AUTOSAR XML (schema 00047)
package /AppSwComponent_Dcm/SwComponentType
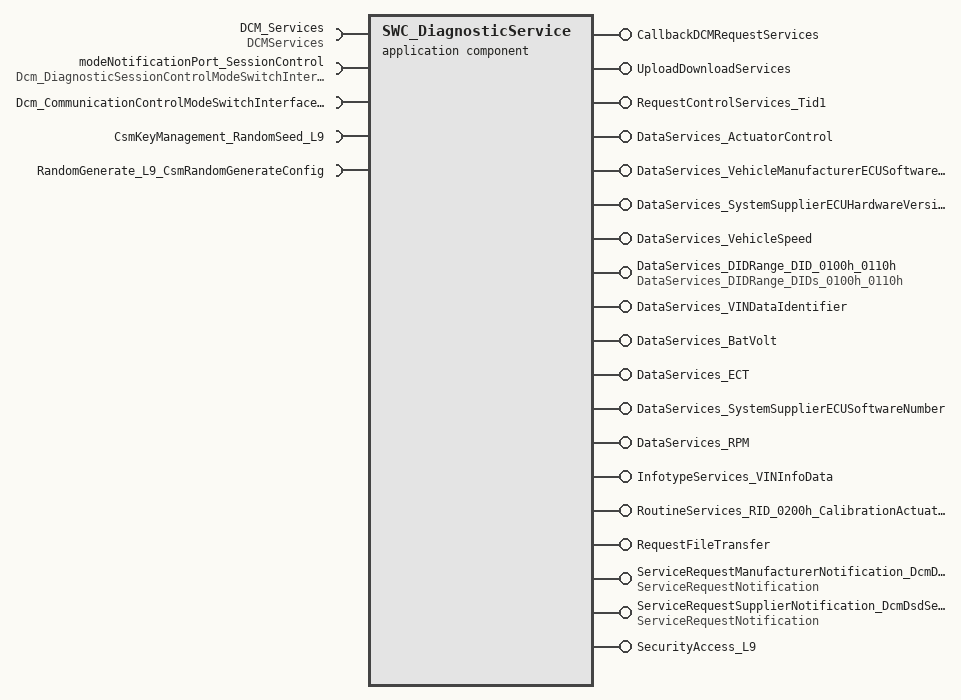
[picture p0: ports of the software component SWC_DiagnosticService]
  application sw component type SWC_DiagnosticService
    provide port CallbackDCMRequestServices: provided-com-specs=[{operation=StartProtocol, queue-length=1}, {operation=StopProtocol, queue-length=1}], provided-interface=CallbackDCMRequestServices
    require port DCM_Services: required-com-specs=[GetActiveProtocol, GetSesCtrlType, GetSecurityLevel, ResetToDefaultSession], required-interface=DCMServices
    require port modeNotificationPort_SessionControl: mode-switch-receiver-com-spec{enhanced-mode-api=true, mode-group=Dcm_DiagnosticSessionControlModeSwitchInterface, supports-asynchronous-mode-switch=true}, required-interface=Dcm_DiagnosticSessionControlModeSwitchInterface
    17 x provide port:
      UploadDownloadServices: provided-interface=UploadDownloadServices
        provided-com-specs:
          operation=ProcessRequestDownload, queue-length=1
          operation=ProcessRequestTransferExit, queue-length=1
          operation=ProcessRequestUpload, queue-length=1
          operation=ProcessTransferDataRead, queue-length=1
          operation=ProcessTransferDataWrite, queue-length=1
      RequestControlServices_Tid1: server-com-spec{operation=RequestControl, queue-length=1}, provided-interface=RequestControlServices_Tid1
      DataServices_ActuatorControl: provided-interface=DataServices_ActuatorControl
        provided-com-specs:
          operation=ConditionCheckRead, queue-length=1
          operation=ReadData, queue-length=1
          operation=WriteData, queue-length=1
          operation=FreezeCurrentState, queue-length=1
          operation=ReturnControlToECU, queue-length=1
          operation=ShortTermAdjustment, queue-length=1
          operation=ResetToDefault, queue-length=1
      DataServices_VehicleManufacturerECUSoftwareVersionNumber: provided-com-specs=[{operation=ReadData, queue-length=1}, {operation=ConditionCheckRead, queue-length=1}], provided-interface=DataServices_VehicleManufacturerECUSoftwareVersionNumber
      DataServices_SystemSupplierECUHardwareVersionNumber: provided-com-specs=[{operation=ReadData, queue-length=1}, {operation=ConditionCheckRead, queue-length=1}], provided-interface=DataServices_SystemSupplierECUHardwareVersionNumber
      DataServices_VehicleSpeed: provided-interface=DataServices_VehicleSpeed
        provided-com-specs:
          operation=ReadData, queue-length=1
          operation=ConditionCheckRead, queue-length=1
          operation=GetScalingInformation, queue-length=1
      DataServices_DIDRange_DID_0100h_0110h: provided-interface=DataServices_DIDRange_DIDs_0100h_0110h
        provided-com-specs:
          operation=IsDidAvailable, queue-length=1
          operation=ReadDidData, queue-length=1
          operation=ReadDidRangeDataLength, queue-length=1
          operation=WriteDidData, queue-length=1
      DataServices_VINDataIdentifier: provided-interface=DataServices_VINDataIdentifier
        provided-com-specs:
          operation=ConditionCheckRead, queue-length=1
          operation=GetScalingInformation, queue-length=1
          operation=ReadData, queue-length=1
          operation=WriteData, queue-length=1
      DataServices_BatVolt: provided-interface=DataServices_BatVolt
        provided-com-specs:
          operation=ReadData, queue-length=1
          operation=ConditionCheckRead, queue-length=1
          operation=WriteData, queue-length=1
      DataServices_ECT: provided-interface=DataServices_ECT
        provided-com-specs:
          operation=ReadData, queue-length=1
          operation=WriteData, queue-length=1
          operation=ConditionCheckRead, queue-length=1
      DataServices_SystemSupplierECUSoftwareNumber: provided-com-specs=[{operation=ReadData, queue-length=1}, {operation=ConditionCheckRead, queue-length=1}], provided-interface=DataServices_SystemSupplierECUSoftwareNumber
      DataServices_RPM: provided-interface=DataServices_RPM
        provided-com-specs:
          operation=ReadData, queue-length=1
          operation=ConditionCheckRead, queue-length=1
          operation=FreezeCurrentState, queue-length=1
          operation=ReturnControlToECU, queue-length=1
          operation=ShortTermAdjustment, queue-length=1
          operation=WriteData, queue-length=1
      InfotypeServices_VINInfoData: server-com-spec{operation=GetInfotypeValueData, queue-length=1}, provided-interface=InfotypeServices_VINInfoData
      RoutineServices_RID_0200h_CalibrationActuator: provided-interface=RoutineServices_RID_0200h_CalibrationActuator
        provided-com-specs:
          operation=Start, queue-length=1
          operation=Stop, queue-length=1
          operation=RequestResults, queue-length=1
      RequestFileTransfer: provided-interface=RequestFileTransfer
        provided-com-specs:
          operation=ProcessRequestAddFile, queue-length=1
          operation=ProcessRequestDeleteFile, queue-length=1
          operation=ProcessRequestReadDir, queue-length=1
          operation=ProcessRequestReadFile, queue-length=1
          operation=ProcessRequestReplaceFile, queue-length=1
          operation=ReadFileOrDir, queue-length=1
          operation=WriteFile, queue-length=1
      ServiceRequestManufacturerNotification_DcmDsdServiceRequestManufacturerNotification0: provided-com-specs=[{operation=Confirmation, queue-length=1}, {operation=Indication, queue-length=1}], provided-interface=ServiceRequestNotification
      ServiceRequestSupplierNotification_DcmDsdServiceRequestSupplierNotification0: provided-com-specs=[{operation=Confirmation, queue-length=1}, {operation=Indication, queue-length=1}], provided-interface=ServiceRequestNotification
    require port Dcm_CommunicationControlModeSwitchInterface_ComMChannel_FD_CAN1: mode-switch-receiver-com-spec{enhanced-mode-api=true, mode-group=Dcm_CommunicationControlModeSwitchInterface_ComMChannel_FD_CAN1, supports-asynchronous-mode-switch=true}, required-interface=Dcm_CommunicationControlModeSwitchInterface_ComMChannel_FD_CAN1
    provide port SecurityAccess_L9: provided-com-specs=[{operation=CompareKey, queue-length=1}, {operation=GetSeed, queue-length=1}], provided-interface=SecurityAccess_L9
    require port CsmKeyManagement_RandomSeed_L9: client-com-spec=RandomSeed, required-interface=CsmKeyManagement_RandomSeed_L9
    require port RandomGenerate_L9_CsmRandomGenerateConfig: client-com-spec=RandomGenerate, required-interface=RandomGenerate_L9_CsmRandomGenerateConfig
    behavior InternalBehaviors_DiagnosticService: data-type-mapping=DcmDiagnosticSessionControl, handle-termination-and-restart=NO-SUPPORT
      operation invoked event OIE_CallbackDCMRequestServices_StartProtocol: start-on-event=CallbackDCMRequestServices_StartProtocol, operation=CallbackDCMRequestServices.StartProtocol
      operation invoked event OIE_CallbackDCMRequestServices_StopProtocol: start-on-event=CallbackDCMRequestServices_StopProtocol, operation=CallbackDCMRequestServices.StopProtocol
      swc mode switch event SMSE_Entry_DiagnosticSessionControlNotification_modeNotificationPort_SessionControl_DcmDiagnosticSessionControl_DCM_DEFAULT_SESSION: start-on-event=DiagnosticSessionControlNotification, activation=ON-ENTRY, mode=modeNotificationPort_SessionControl.Dcm_DiagnosticSessionControlModeSwitchInterface.DCM_DEFAULT_SESSION
      swc mode switch event SMSE_Entry_DiagnosticSessionControlNotification_modeNotificationPort_SessionControl_DcmDiagnosticSessionControl_DCM_EXTENDED_DIAGNOSTIC_SESSION: start-on-event=DiagnosticSessionControlNotification, activation=ON-ENTRY, mode=modeNotificationPort_SessionControl.Dcm_DiagnosticSessionControlModeSwitchInterface.DCM_EXTENDED_DIAGNOSTIC_SESSION
      59 x operation invoked event:
        OIE_UploadDownloadServices_ProcessTransferDataRead: start-on-event=UploadDownloadServices_ProcessTransferDataRead, operation=UploadDownloadServices.ProcessTransferDataRead
        OIE_UploadDownloadServices_ProcessRequestDownload: start-on-event=UploadDownloadServices_ProcessRequestDownload, operation=UploadDownloadServices.ProcessRequestDownload
        OIE_UploadDownloadServices_ProcessTransferDataWrite: start-on-event=UploadDownloadServices_ProcessTransferDataWrite, operation=UploadDownloadServices.ProcessTransferDataWrite
        OIE_UploadDownloadServices_ProcessRequestTransferExit: start-on-event=UploadDownloadServices_ProcessRequestTransferExit, operation=UploadDownloadServices.ProcessRequestTransferExit
        OIE_UploadDownloadServices_ProcessRequestUpload: start-on-event=UploadDownloadServices_ProcessRequestUpload, operation=UploadDownloadServices.ProcessRequestUpload
        OIE_RequestControlServices_Tid1_RequestControl: start-on-event=RequestControlServices_Tid1_RequestControl, operation=RequestControlServices_Tid1.RequestControl
        OIE_ActuatorControl_ReadData: start-on-event=ActuatorControl_ReadData, operation=DataServices_ActuatorControl.ReadData
        OIE_ActuatorControl_WriteData: start-on-event=ActuatorControl_WriteData, operation=DataServices_ActuatorControl.WriteData
        OIE_ActuatorControl_ConditionCheckRead: start-on-event=ActuatorControl_ConditionCheckRead, operation=DataServices_ActuatorControl.ConditionCheckRead
        OIE_ActuatorControl_ResetToDefault: start-on-event=ActuatorControl_ResetToDefault, operation=DataServices_ActuatorControl.ResetToDefault
        OIE_ActuatorControl_FreezeCurrentState: start-on-event=ActuatorContro_FreezeCurrentState, operation=DataServices_ActuatorControl.FreezeCurrentState
        OIE_ActuatorControl_ReturnControlToECU: start-on-event=ActuatorControl_ReturnControlToECU, operation=DataServices_ActuatorControl.ReturnControlToECU
        OIE_ActuatorControl_ShortTermAdjustment: start-on-event=ActuatorControl_ShortTermAdjustment, operation=DataServices_ActuatorControl.ShortTermAdjustment
        OIE_DID_0100h_0110h_ReadDidData: start-on-event=DID_0100h_0110h_ReadDidData, operation=DataServices_DIDRange_DID_0100h_0110h.ReadDidData
        OIE_DID_0100h_0110h_WriteDidData: start-on-event=DID_0100h_0110h_WriteDidData, operation=DataServices_DIDRange_DID_0100h_0110h.WriteDidData
        OIE_DID_0100h_0110h_IsDidAvailable: start-on-event=DID_0100h_0110h_IsDidAvailable, operation=DataServices_DIDRange_DID_0100h_0110h.IsDidAvailable
        OIE_DID_0100h_0110h_ReadDidRangeDataLength: start-on-event=DID_0100h_0110h_ReadDidRangeDataLength, operation=DataServices_DIDRange_DID_0100h_0110h.ReadDidRangeDataLength
        OIE_VehicleSpeed_GetScalingInformation: start-on-event=VehicleSpeed_GetScalingInformation, operation=DataServices_VehicleSpeed.GetScalingInformation
        OIE_VINDataIdentifier_ConditionCheckRead: start-on-event=VINDataIdentifier_ConditionCheckRead, operation=DataServices_VINDataIdentifier.ConditionCheckRead
        OIE_VehicleManufacturerECUSoftwareVersionNumber_ConditionCheckRead: start-on-event=VehicleManufacturerECUSoftwareVersionNumber_ConditionCheckRead, operation=DataServices_VehicleManufacturerECUSoftwareVersionNumber.ConditionCheckRead
        OIE_RPM_WriteData: start-on-event=RPM_WriteData, operation=DataServices_RPM.WriteData
        OIE_VINDataIdentifier_WriteData: start-on-event=VINDataIdentifier_WriteData, operation=DataServices_VINDataIdentifier.WriteData
        OIE_SystemSupplierECUHardwareVersionNumber_ReadData: start-on-event=SystemSupplierECUHardwareVersionNumber_ReadData, operation=DataServices_SystemSupplierECUHardwareVersionNumber.ReadData
        OIE_BatVolt_WriteData: start-on-event=BatVolt_WriteData, operation=DataServices_BatVolt.WriteData
        OIE_ECT_ReadData: start-on-event=ECT_ReadData, operation=DataServices_ECT.ReadData
        OIE_ECT_WriteData: start-on-event=ECT_WriteData, operation=DataServices_ECT.WriteData
        OIE_VehicleManufacturerECUSoftwareVersionNumber_ReadData: start-on-event=VehicleManufacturerECUSoftwareVersionNumber_ReadData, operation=DataServices_VehicleManufacturerECUSoftwareVersionNumber.ReadData
        OIE_SystemSupplierECUSoftwareNumber_ConditionCheckRead: start-on-event=SystemSupplierECUSoftwareNumber_ConditionCheckRead, operation=DataServices_SystemSupplierECUSoftwareNumber.ConditionCheckRead
        OIE_RPM_FreezeCurrentState: start-on-event=RPM_FreezeCurrentState, operation=DataServices_RPM.FreezeCurrentState
        OIE_BatVolt_ConditionCheckRead: start-on-event=BatVolt_ConditionCheckRead, operation=DataServices_BatVolt.ConditionCheckRead
        OIE_SystemSupplierECUHardwareVersionNumber_ConditionCheckRead: start-on-event=SystemSupplierECUHardwareVersionNumber_ConditionCheckRead, operation=DataServices_SystemSupplierECUHardwareVersionNumber.ConditionCheckRead
        OIE_BatVolt_ReadData: start-on-event=BatVolt_ReadData, operation=DataServices_BatVolt.ReadData
        OIE_RPM_ReadData: start-on-event=RPM_ReadData, operation=DataServices_RPM.ReadData
        OIE_VINDataIdentifier_ReadData: start-on-event=VINDataIdentifier_ReadData, operation=DataServices_VINDataIdentifier.ReadData
        OIE_RPM_ShortTermAdjustment: start-on-event=RPM_ShortTermAdjustment, operation=DataServices_RPM.ShortTermAdjustment
        OIE_RPM_ConditionCheckRead: start-on-event=RPM_ConditionCheckRead, operation=DataServices_RPM.ConditionCheckRead
        OIE_ECT_ConditionCheckRead: start-on-event=ECT_ConditionCheckRead, operation=DataServices_ECT.ConditionCheckRead
        OIE_VehicleSpeed_ConditionCheckRead: start-on-event=VehicleSpeed_ConditionCheckRead, operation=DataServices_VehicleSpeed.ConditionCheckRead
        OIE_RPM_ReturnControlToECU: start-on-event=RPM_ReturnControlToECU, operation=DataServices_RPM.ReturnControlToECU
        OIE_VehicleSpeed_ReadData: start-on-event=VehicleSpeed_ReadData, operation=DataServices_VehicleSpeed.ReadData
        OIE_SystemSupplierECUSoftwareNumber_ReadData: start-on-event=SystemSupplierECUSoftwareNumber_ReadData, operation=DataServices_SystemSupplierECUSoftwareNumber.ReadData
        OIE_VINDataIdentifier_GetScalingInformation: start-on-event=VINDataIdentifier_GetScalingInformation, operation=DataServices_VINDataIdentifier.GetScalingInformation
        OIE_InfotypeServices_VINInfoData_GetInfotypeValueData: start-on-event=InfotypeServices_VINInfoData_GetInfotypeValueData, operation=InfotypeServices_VINInfoData.GetInfotypeValueData
        OIE_RoutineServices_RID_0200h_CalibrationActuator_Start: start-on-event=RID_0200h_CalibrationActuator_Start, operation=RoutineServices_RID_0200h_CalibrationActuator.Start
        OIE_RoutineServices_RID_0200h_CalibrationActuator_Stop: start-on-event=RID_0200h_CalibrationActuator_Stop, operation=RoutineServices_RID_0200h_CalibrationActuator.Stop
        OIE_RoutineServices_RID_0200h_CalibrationActuator_RequestResults: start-on-event=RID_0200h_CalibrationActuator_RequestResults, operation=RoutineServices_RID_0200h_CalibrationActuator.RequestResults
        OIE_RequestFileTransfer_ProcessRequestAddFile: start-on-event=RequestFileTransfer_ProcessRequestAddFile, operation=RequestFileTransfer.ProcessRequestAddFile
        OIE_RequestFileTransfer_ProcessRequestDeleteFile: start-on-event=RequestFileTransfer_ProcessRequestDeleteFile, operation=RequestFileTransfer.ProcessRequestDeleteFile
        OIE_RequestFileTransfer_ProcessRequestReadDir: start-on-event=RequestFileTransfer_ProcessRequestReadDir, operation=RequestFileTransfer.ProcessRequestReadDir
        OIE_RequestFileTransfer_ProcessRequestReadFile: start-on-event=RequestFileTransfer_ProcessRequestReadFile, operation=RequestFileTransfer.ProcessRequestReadFile
        OIE_RequestFileTransfer_ProcessRequestReplaceFile: start-on-event=RequestFileTransfer_ProcessRequestReplaceFile, operation=RequestFileTransfer.ProcessRequestReplaceFile
        OIE_RequestFileTransfer_ReadFileOrDir: start-on-event=RequestFileTransfer_ReadFileOrDir, operation=RequestFileTransfer.ReadFileOrDir
        OIE_RequestFileTransfer_WriteFile: start-on-event=RequestFileTransfer_WriteFile, operation=RequestFileTransfer.WriteFile
        OIE_ServiceRequestManufacturerNotification_DcmDsdServiceRequestManufacturerNotification0_Confirmation: start-on-event=DcmDsdServiceRequestManufacturerNotification0_Confirmation, operation=ServiceRequestManufacturerNotification_DcmDsdServiceRequestManufacturerNotification0.Confirmation
        OIE_ServiceRequestManufacturerNotification_DcmDsdServiceRequestManufacturerNotification0_Indication: start-on-event=DcmDsdServiceRequestManufacturerNotification0_Indication, operation=ServiceRequestManufacturerNotification_DcmDsdServiceRequestManufacturerNotification0.Indication
        OIE_ServiceRequestSupplierNotification_DcmDsdServiceRequestSupplierNotification0_Confirmation: start-on-event=DcmDsdServiceRequestSupplierNotification0_Confirmation, operation=ServiceRequestSupplierNotification_DcmDsdServiceRequestSupplierNotification0.Confirmation
        OIE_ServiceRequestSupplierNotification_DcmDsdServiceRequestSupplierNotification0_Indication: start-on-event=DcmDsdServiceRequestSupplierNotification0_Indication, operation=ServiceRequestSupplierNotification_DcmDsdServiceRequestSupplierNotification0.Indication
        OIE_L9_CompareKey_SecurityAccess_L9_CompareKey: start-on-event=L9_CompareKey, operation=SecurityAccess_L9.CompareKey
        OIE_L9_GetSeed_SecurityAccess_L9_GetSeed: start-on-event=L9_GetSeed, operation=SecurityAccess_L9.GetSeed
      63 x runnable, all with can-be-invoked-concurrently=true:
        DO_NOT_REMPOVE: symbol=AppDcm_Runnable
          4 x sync call:
            SSCP_GetActiveProtocol: operation=DCM_Services.GetActiveProtocol
            SSCP_GetSesCtrlType: operation=DCM_Services.GetSesCtrlType
            SSCP_GetSecurityLevel: operation=DCM_Services.GetSecurityLevel
            SSCP_ResetToDefaultSession: operation=DCM_Services.ResetToDefaultSession
        CallbackDCMRequestServices_StartProtocol: symbol=AppDcm_StartProtocol
        CallbackDCMRequestServices_StopProtocol: symbol=AppDcm_StopProtocol
        DiagnosticSessionControlNotification: symbol=AppDcm_DiagnosticSessionControlNotification
          mode-access-point mode-group=modeNotificationPort_SessionControl.Dcm_DiagnosticSessionControlModeSwitchInterface:
            ident MRAP_DiagnosticSessionControlNotification_modeNotificationPort_SessionControl_DcmDiagnosticSessionControl
        UploadDownloadServices_ProcessTransferDataRead: symbol=AppDcm_UploadDownloadServices_ProcessTransferDataRead
        UploadDownloadServices_ProcessRequestDownload: symbol=AppDcm_UploadDownloadServices_ProcessRequestDownload
        UploadDownloadServices_ProcessTransferDataWrite: symbol=AppDcm_UploadDownloadServices_ProcessTransferDataWrite
        UploadDownloadServices_ProcessRequestTransferExit: symbol=AppDcm_UploadDownloadServices_ProcessRequestTransferExit
        UploadDownloadServices_ProcessRequestUpload: symbol=AppDcm_UploadDownloadServices_ProcessRequestUpload
        RequestControlServices_Tid1_RequestControl: symbol=AppDcm_RequestControlServices_Tid1_RequestControl
        ActuatorControl_ReadData: symbol=AppDcm_ReadData_ActuatorControl
        ActuatorControl_WriteData: symbol=AppDcm_WriteData_ActuatorControl
        ActuatorControl_ConditionCheckRead: symbol=AppDcm_ConditionCheckRead_ActuatorControl
        ActuatorControl_ResetToDefault: symbol=AppDcm_ResetToDefault_ActuatorControl
        ActuatorControl_ReturnControlToECU: symbol=AppDcm_ReturnControlToECU_ActuatorControl
        ActuatorContro_FreezeCurrentState: symbol=AppDcm_FreezeCurrentState_ActuatorControl
        ActuatorControl_ShortTermAdjustment: symbol=AppDcm_ShortTermAdjustment_ActuatorControl
        DID_0100h_0110h_ReadDidData: symbol=AppDcm_ReadDidData_DID_0100h_0110h
        DID_0100h_0110h_WriteDidData: symbol=AppDcm_WriteDidData_DID_0100h_0110h
        DID_0100h_0110h_IsDidAvailable: symbol=AppDcm_IsDidAvailable_DID_0100h_0110h
        DID_0100h_0110h_ReadDidRangeDataLength: symbol=AppDcm_ReadDidRangeDataLength_DID_0100h_0110h
        SystemSupplierECUHardwareVersionNumber_ConditionCheckRead: symbol=AppDcm_ConditionCheckRead_SystemSupplierECUHardwareVersionNumber
        VehicleSpeed_GetScalingInformation: symbol=AppDcm_GetScalingInformation_VehicleSpeed
        SystemSupplierECUHardwareVersionNumber_ReadData: symbol=AppDcm_ReadData_SystemSupplierECUHardwareVersionNumber
        SystemSupplierECUSoftwareNumber_ConditionCheckRead: symbol=AppDcm_ConditionCheckRead_SystemSupplierECUSoftwareNumber
        VehicleSpeed_ReadData: symbol=AppDcm_ReadData_VehicleSpeed
        VehicleManufacturerECUSoftwareVersionNumber_ReadData: symbol=AppDcm_ReadData_VehicleManufacturerECUSoftwareVersionNumber
        VINDataIdentifier_GetScalingInformation: symbol=AppDcm_GetScalingInformation_VINDataIdentifier
        VINDataIdentifier_WriteData: symbol=AppDcm_WriteData_VINDataIdentifier
        VehicleManufacturerECUSoftwareVersionNumber_ConditionCheckRead: symbol=AppDcm_ConditionCheckRead_VehicleManufacturerECUSoftwareVersionNumber
        SystemSupplierECUSoftwareNumber_ReadData: symbol=AppDcm_ReadData_SystemSupplierECUSoftwareNumber
        VINDataIdentifier_ConditionCheckRead: symbol=AppDcm_ConditionCheckRead_VINDataIdentifier
        VINDataIdentifier_ReadData: symbol=AppDcm_ReadData_VINDataIdentifier
        VehicleSpeed_ConditionCheckRead: symbol=AppDcm_ConditionCheckRead_VehicleSpeed
        BatVolt_ReadData: symbol=AppDcm_ReadData_BatVolt
        ECT_WriteData: symbol=AppDcm_WriteData_ECT
        RPM_FreezeCurrentState: symbol=AppDcm_FreezeCurrentState_RPM
        BatVolt_WriteData: symbol=AppDcm_WriteData_BatVolt
        RPM_ReturnControlToECU: symbol=AppDcm_ReturnControlToECU_RPM
        RPM_ShortTermAdjustment: symbol=AppDcm_ShortTermAdjustment_RPM
        RPM_ReadData: symbol=AppDcm_ReadData_RPM
        BatVolt_ConditionCheckRead: symbol=AppDcm_ConditionCheckRead_BatVolt
        RPM_WriteData: symbol=AppDcm_WriteData_RPM
        RPM_ConditionCheckRead: symbol=AppDcm_ConditionCheckRead_RPM
        ECT_ReadData: symbol=AppDcm_ReadData_ECT
        ECT_ConditionCheckRead: symbol=AppDcm_ConditionCheckRead_ECT
        InfotypeServices_VINInfoData_GetInfotypeValueData: symbol=AppDcm_InfotypeServices_VINInfoData_GetInfotypeValueData
        RID_0200h_CalibrationActuator_Start: symbol=AppDcm_Start_CalibrationActuator
        RID_0200h_CalibrationActuator_Stop: symbol=AppDcm_Stop_CalibrationActuator
        RID_0200h_CalibrationActuator_RequestResults: symbol=AppDcm_RequestResults_CalibrationActuator
        RequestFileTransfer_ProcessRequestAddFile: symbol=AppDcm_RequestFileTransfer_ProcessRequestAddFile
        RequestFileTransfer_ProcessRequestDeleteFile: symbol=AppDcm_RequestFileTransfer_ProcessRequestDeleteFile
        RequestFileTransfer_ProcessRequestReadDir: symbol=AppDcm_RequestFileTransfer_ProcessRequestReadDir
        RequestFileTransfer_ProcessRequestReadFile: symbol=AppDcm_RequestFileTransfer_ProcessRequestReadFile
        RequestFileTransfer_ProcessRequestReplaceFile: symbol=AppDcm_RequestFileTransfer_ProcessRequestReplaceFile
        RequestFileTransfer_ReadFileOrDir: symbol=AppDcm_RequestFileTransfer_ReadFileOrDir
        RequestFileTransfer_WriteFile: symbol=App_Dcm_RequestFileTransfer_WriteFile
        DcmDsdServiceRequestManufacturerNotification0_Confirmation: symbol=ServiceRequestManufacturerNotification_Confirmation
        DcmDsdServiceRequestManufacturerNotification0_Indication: symbol=ServiceRequestManufacturerNotification_Indication
        DcmDsdServiceRequestSupplierNotification0_Confirmation: symbol=ServiceRequestSupplierNotification_Confirmation
        DcmDsdServiceRequestSupplierNotification0_Indication: symbol=ServiceRequestSupplierNotification_Indication
        L9_CompareKey: symbol=AppDcm_CompareKey_L9
        L9_GetSeed: symbol=AppDcm_GetSeed_L9
          sync call SSCP_L9_GetSeed_CsmKeyManagement_RandomSeed_L9_RandomSeed: operation=CsmKeyManagement_RandomSeed_L9.RandomSeed
          sync call SSCP_L9_GetSeed_RandomGenerate_L9_CsmRandomGenerateConfig_RandomGenerate: operation=RandomGenerate_L9_CsmRandomGenerateConfig.RandomGenerate
      swc service dependency SwcServiceDependency0: assigned-ports=role-based-port-assignment={port-prototype=modeNotificationPort_SessionControl, role=Custom}
        service-needs:
          bsw mgr needs BswMgrNeeds
  swc implementation App_Dcm_Implementation: behavior=InternalBehaviors_DiagnosticService
    code-descriptors:
      code Default
